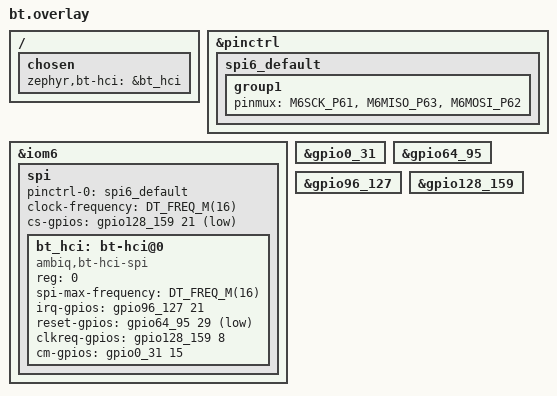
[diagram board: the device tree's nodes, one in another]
/*
 * TEST ONLY: the evb's EM9305 HCI node on IOM6 (from the fork's apollo510b_evb, Apache-2.0,
 * Ambiq Micro), for the rule 8 negative builds in scripts/test.sh. Never used for an image.
 */
&pinctrl {
	spi6_default: spi6_default {
		group1 {
			pinmux = <M6SCK_P61>, <M6MISO_P63>, <M6MOSI_P62>;
		};
	};
};

&iom6 {
	spi {
		pinctrl-0 = <&spi6_default>;
		pinctrl-names = "default";
		clock-frequency = <DT_FREQ_M(16)>;
		cs-gpios = <&gpio128_159 21 (GPIO_ACTIVE_LOW | GPIO_PULL_UP)>;
		status = "okay";

		bt_hci: bt-hci@0 {
			compatible = "ambiq,bt-hci-spi";
			reg = <0>;
			spi-max-frequency = <DT_FREQ_M(16)>;
			irq-gpios = <&gpio96_127 21 GPIO_ACTIVE_HIGH>;
			reset-gpios = <&gpio64_95 29 GPIO_ACTIVE_LOW>;
			clkreq-gpios = <&gpio128_159 8 GPIO_ACTIVE_HIGH>;
			cm-gpios = <&gpio0_31 15 GPIO_ACTIVE_HIGH>;
			status = "okay";
		};
	};
};

/ {
	chosen {
		zephyr,bt-hci = &bt_hci;
	};
};

&gpio0_31 { status = "okay"; };
&gpio64_95 { status = "okay"; };
&gpio96_127 { status = "okay"; };
&gpio128_159 { status = "okay"; };
